# PIC32CX1012BZ24032 register map
Vendor: Microchip Technology; Series: BZ24; File version: 0
CPU: CM4 r0p1, little endian, MPU, FPU, 3 interrupt priority bits
Registers are 32-bit, read-write, reset 0x0 unless marked. A register's access mark holds for its fields unless they carry their own. Offsets are from the block's base; [hi:lo] are bit positions; {n}, {i} and the like mark numbered series; 'fields as' and 'values as' point back to an identical list.

## CFG
Base 0x44000000; register names take the prefix CFG_
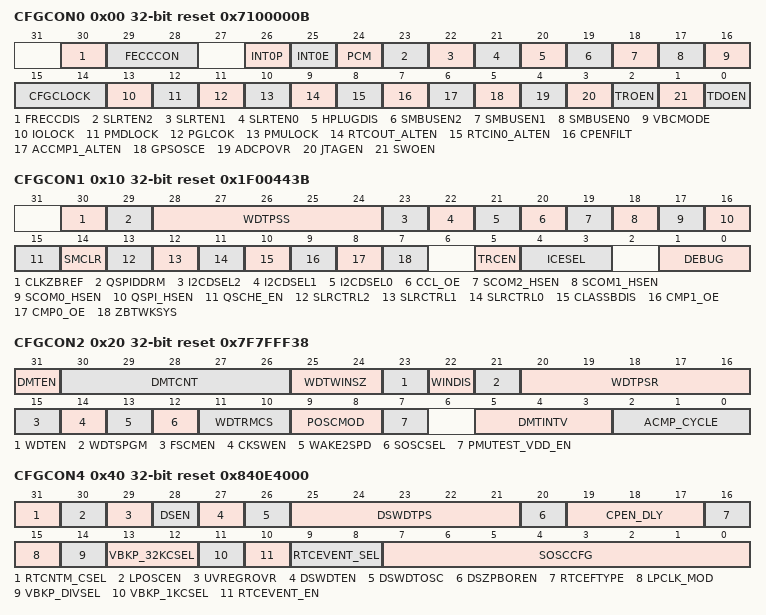
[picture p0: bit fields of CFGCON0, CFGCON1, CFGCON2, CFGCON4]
0x00 CFGCON0 reset 0x7100000B
  [30] FRECCDIS — Flex RAM ECC Control
  [29:28] FECCCON — Flash ECC Control
  [26] INT0P — INT0P Polarity
  [25] INT0E — INT0 Enable
  [24] PCM — PCHE I/D Cacheable Mode
  [23] SLRTEN2 — SLRT Enable for SERCOM2
  [22] SLRTEN1 — SLRT Enable for SERCOM1
  [21] SLRTEN0 — SLRT Enable for SERCOM0
  [20] HPLUGDIS — Hot Plugging Disable
  [19] SMBUSEN2 — SMBus Enable for SERCOM2
  [18] SMBUSEN1 — SMBus Enable for SERCOM1
  [17] SMBUSEN0 — SMBus Enable for SERCOM0
  [16] VBCMODE — VBC Operating Mode
  [15:14] CFGCLOCK — Configuration Register Lock
  [13] IOLOCK
  [12] PMDLOCK — Peripheral Module Disable (PMD) LOCK
  [11] PGLCOK — Permission Group LOCK
  [10] PMULOCK — PMU Controller Register LOCK
  [9] RTCOUT_ALTEN — RTCOUT Alternate Enable
  [8] RTCIN0_ALTEN — RTCIN0 Alternate Enable
  [7] CPENFILT — ADC CP Filter Enable
  [6] ACCMP1_ALTEN — AC CMP1 Alternate Enable
  [5] GPSOSCE — GPIO/SOSC Enable
  [4] ADCPOVR — ADC Charge Pump Override
  [3] JTAGEN — JTAG Enable
  [2] TROEN — Trace Output Enable
  [1] SWOEN — SWO enable on 2-wire debug interface
  [0] TDOEN — TDO enable for 2-wire JTAG
{0x4+0x10*i} CFGCON{i}CLR (i=0..2) — Bit clear register
{0x8+0x10*i} CFGCON{i}SET (i=0..2) — Bit set register
{0xC+0x10*i} CFGCON{i}INV (i=0..2) — Bit invert register
0x10 CFGCON1 reset 0x1F00443B
  [30] CLKZBREF — External Reference Clock ZB Enable
  [29] QSPIDDRM — QSPI DDR Mode Clock Enable
  [28:24] WDTPSS — Watchdog Timer Post-scale Select Sleep
  [23] I2CDSEL2 — I2C Delay Select for SERCOM2
  [22] I2CDSEL1 — I2C Delay Select for SERCOM1
  [21] I2CDSEL0 — I2C Delay Select for SERCOM0
  [20] CCL_OE — CCL Pads (via PPS) Output Enable
  [19] SCOM2_HSEN — SERCOM2 (Direct)High Speed Pin Enable
  [18] SCOM1_HSEN — SERCOM1 (Direct)High Speed Pin Enable
  [17] SCOM0_HSEN — SERCOM0 (Direct)High Speed Pin Enable
  [16] QSPI_HSEN — QSPI (Direct) Enable
  [15] QSCHE_EN — QSPI Address Space Cache Attribute
  [14] SMCLR — Selects CRU handling of MCLR Control
  [13] SLRCTRL2 — I2C Slew Rate Control for SERCOM2
  [12] SLRCTRL1 — I2C Slew Rate Control for SERCOM1
  [11] SLRCTRL0 — I2C Slew Rate Control for SERCOM0
  [10] CLASSBDIS — Disable CLASSB Device Functionality
  [9] CMP1_OE — Analog Comparator-1 Output Enable
  [8] CMP0_OE — Analog Comparator-0 Output Enable
  [7] ZBTWKSYS — ZBT Subsystem External Wake-up source
  [5] TRCEN — Trace Enable
  [4:3] ICESEL — EMUC/EMUD Communication Channel Select
  [1:0] DEBUG — Background Debugger Access Selection
0x20 CFGCON2 reset 0x7F7FFF38
  [31] DMTEN — Dead Man Timer Enable
  [30:26] DMTCNT — Dead Man Timer Count Select
  [25:24] WDTWINSZ — Watchdog Timer Window Size
  [23] WDTEN — Watchdog Timer Enable
  [22] WINDIS — Windowed Watchdog Timer Disable
  [21] WDTSPGM — Watchdog Timer Stop during Flash Programming
  [20:16] WDTPSR — Watchdog Timer Post-scale Select Run
  [15] FSCMEN — Fail-Safe Clock Monitor Enable
  [14] CKSWEN — Software Clock Switching Enable
  [13] WAKE2SPD — 2-Speed startup enabled in Sleep mode
  [12] SOSCSEL — SOSC Selection Configuration
  [11:10] WDTRMCS — WDT RUN Mode Clock Select
  [9:8] POSCMOD — Primary Oscillator Configuration
  [7] PMUTEST_VDD_EN — PMU Test Output or VDD/2 Enable via ADC IE12
  [5:3] DMTINTV — Dead Man Timer Count Window Interval
  [2:0] ACMP_CYCLE — AC SIB Comparator Result Wait Cycles
0x40 CFGCON4 reset 0x840E4000
  [31] RTCNTM_CSEL — RTC Counter Mode Clock Select
  [30] LPOSCEN — Low Power (Secondary) Oscillator Enable
  [29] UVREGROVR — ULPVREG Retention Mode Override
  [28] DSEN — Deep Sleep Bit Enable
  [27] DSWDTEN — Deep Sleep Watchdog Timer Enable
  [26] DSWDTOSC — Deep Sleep Watchdog Timer Reference Clock Select
  [25:21] DSWDTPS — Deep Sleep Watchdog Timer Postscale Select
  [20] DSZPBOREN — Deep Sleep Zero-Power BOR Enable
  [19:17] CPEN_DLY — Charge-pump ready digital delay
  [16] RTCEFTYPE — RTC Event Type
  [15] LPCLK_MOD — LPCLK modifier in counter/delay mode
  [14] VBKP_DIVSEL — VDDBUKPCORE LPCLK Clock Divider Selection
  [13:12] VBKP_32KCSEL — VDDBUKPCORE 32KHz clock source selection
  [11] VBKP_1KCSEL — VDDBUKPCORE LPCLK Clock Selection
  [10] RTCEVENT_EN — Pad Output Enable for MCHP legacy RTC event output
  [9:8] RTCEVENT_SEL — RTC Event Selection
  [7:0] SOSCCFG — SOSC Configuration
0x44 CFGCON4CLR — Bit clear register
0x48 CFGCON4SET — Bit set register
0x4C CFGCON4INV — Bit invert register
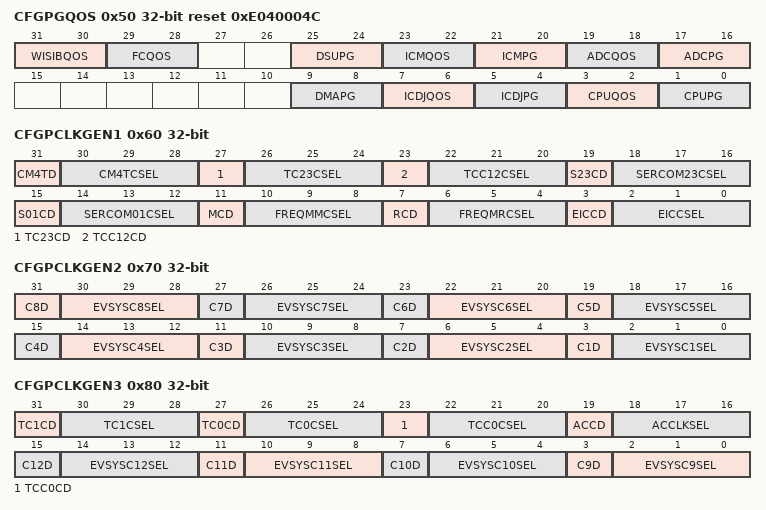
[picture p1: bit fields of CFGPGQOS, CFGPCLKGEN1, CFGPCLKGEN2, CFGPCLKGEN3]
0x50 CFGPGQOS reset 0xE040004C
  [31:30] WISIBQOS — Wireless SIB QOS Control
  [29:28] FCQOS — FC Controller QOS Control
  [25:24] DSUPG — DSU Permission Group
  [23:22] ICMQOS — ICM QOS Control
  [21:20] ICMPG — ICM Permission Group
  [19:18] ADCQOS — ADC Controller QOS Control
  [17:16] ADCPG — ADC Controller Permission Group
  [9:8] DMAPG — DMA (Rd/Wr) Permission Group
  [7:6] ICDJQOS — ICD-JTAG Bus QOS Control
  [5:4] ICDJPG — ICD-JTAG Permission Group
  [3:2] CPUQOS — CPU I/D and System Bus QOS Control
  [1:0] CPUPG — CPU (Code) Permission Group
0x54 CFGPGQOSCLR — Bit clear register
0x58 CFGPGQOSSET — Bit set register
0x5C CFGPGQOSINV — Bit invert register
0x60 CFGPCLKGEN1
  [31] CM4TD — CM4T Clock Disable
    1=ON (Enable PGCLK); 0=OFF (Disable PGCLK)
  [30:28] CM4TCSEL — CM4T Clock Selection
    0=NO_CLK (No Clock); {v}=REFO{v} (Reference Clock {v}) (v=1..6); 7=LPCLK (32 KHz Low Power Clock)
  [27] TC23CD — TC2/3 Clock Disable
    1=ON (Enable PGCLK); 0=OFF (Disable PGCLK)
  [26:24] TC23CSEL — TC2/3 Clock Selection
    values as CM4TCSEL
  [23] TCC12CD — TCC1/2 Clock Disable
    1=ON (Enable PGCLK); 0=OFF (Disable PGCLK)
  [22:20] TCC12CSEL — TCC1/2 Clock Selection
    values as CM4TCSEL
  [19] S23CD — SERCOM2/3 Clock Disable
    1=ON (Enable PGCLK); 0=OFF (Disable PGCLK)
  [18:16] SERCOM23CSEL — SERCOM2/3 Clock Selection
    values as CM4TCSEL
  [15] S01CD — SERCOM0/1 Clock Disable
    1=ON (Enable PGCLK); 0=OFF (Disable PGCLK)
  [14:12] SERCOM01CSEL — SERCOM0/1 Clock Selection
    values as CM4TCSEL
  [11] MCD — FREQMMC Clock Disable
    1=ON (Enable PGCLK); 0=OFF (Disable PGCLK)
  [10:8] FREQMMCSEL — FREQMMC Clock Selection
    values as CM4TCSEL
  [7] RCD — FREQMRC Clock Disable
    1=ON (Enable PGCLK); 0=OFF (Disable PGCLK)
  [6:4] FREQMRCSEL — FREQMRC Clock Selection
    values as CM4TCSEL
  [3] EICCD — EIC Clock Disable
    1=ON (Enable PGCLK); 0=OFF (Disable PGCLK)
  [2:0] EICCSEL — EIC Clock Selection
    values as CM4TCSEL
{0x54+0x10*i} CFGPCLKGEN{i}CLR (i=1..3) — Bit clear register
{0x58+0x10*i} CFGPCLKGEN{i}SET (i=1..3) — Bit set register
{0x5C+0x10*i} CFGPCLKGEN{i}INV (i=1..3) — Bit invert register
0x70 CFGPCLKGEN2
  [31] C8D — C8D Clock Disable
    1=ON (Enable PGCLK); 0=OFF (Disable PGCLK)
  [4n-2:4n-4] EVSYSC{n}SEL (n=1..8) — EVSYSC{n} Peripheral Clock Selection
    values as CFGPCLKGEN1.CM4TCSEL
  [27] C7D — C7D Clock Disable
    1=ON (Enable PGCLK); 0=OFF (Disable PGCLK)
  [4n-1] C{n}D (n=1..6) — EVSYSC{n} Clock Disable
    1=ON (Enable PGCLK); 0=OFF (Disable PGCLK)
0x80 CFGPCLKGEN3
  [31] TC1CD — TC1 Clock Disable
    1=ON (Enable PGCLK); 0=OFF (Disable PGCLK)
  [30:28] TC1CSEL — TC1 Peripheral Clock Selection
    values as CFGPCLKGEN1.CM4TCSEL
  [27] TC0CD — TC0 Clock Disable
    1=ON (Enable PGCLK); 0=OFF (Disable PGCLK)
  [26:24] TC0CSEL — TC0 Peripheral Clock Selection
    values as CFGPCLKGEN1.CM4TCSEL
  [23] TCC0CD — TCC0 Clock Disable
    1=ON (Enable PGCLK); 0=OFF (Disable PGCLK)
  [22:20] TCC0CSEL — TCC0 Peripheral Clock Selection
    values as CFGPCLKGEN1.CM4TCSEL
  [19] ACCD — AC Clock Disable
    1=ON (Enable PGCLK); 0=OFF (Disable PGCLK)
  [18:16] ACCLKSEL — AC Peripheral Clock Selection
    values as CFGPCLKGEN1.CM4TCSEL
  [4n-33] C{n}D (n=9..12) — C{n}D Clock Disable
    1=ON (Enable PGCLK); 0=OFF (Disable PGCLK)
  [4n-34:4n-36] EVSYSC{n}SEL (n=9..12) — EVSYSC{n} Peripheral Clock Selection
    values as CFGPCLKGEN1.CM4TCSEL
0x90 ID ro — Device ID
0xA0 USER_ID
  [15:0] USER_ID — User unique ID, readable using the JTAG USER_ID instruction
0xA4 USER_IDCLR — Bit clear register
0xA8 USER_IDSET — Bit set register
0xAC USER_IDINV — Bit invert register
0xB0 SYSKEY
  [31:0] SYSKEY — System Key
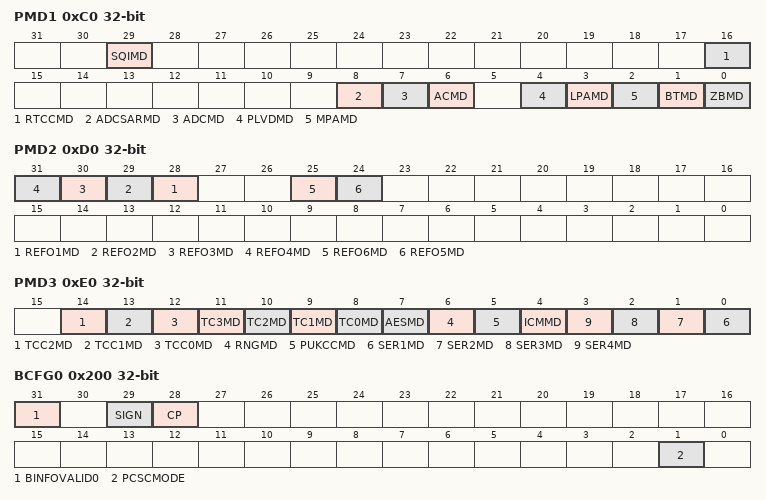
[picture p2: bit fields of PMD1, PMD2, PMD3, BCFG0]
0xC0 PMD1
  [29] SQIMD — SQI Module Disable
  [16] RTCCMD — RTCC Module Disable
  [8] ADCSARMD — Shared ADC SAR Core Module Disable
  [7] ADCMD — ADC Controller Module Disable
  [6] ACMD — AC Module Disable
  [4] PLVDMD — PLVD Module Disable
  [3] LPAMD — RF LPA Module Disable
  [2] MPAMD — RF MPA Module Disable
  [1] BTMD — Bluetooth Module Disable
  [0] ZBMD — ZigBee Module Disable
{0xB4+0x10*i} PMD{i}CLR (i=1..3) — Bit clear register
{0xB8+0x10*i} PMD{i}SET (i=1..3) — Bit set register
{0xBC+0x10*i} PMD{i}INV (i=1..3) — Bit invert register
0xD0 PMD2
  [n+27] REFO{n}MD (n=1..4) — Reference (Clock) Out {n} Module Disable
  [25] REFO6MD — Reference (Clock) Out 6 Module Disable
  [24] REFO5MD — Reference (Clock) Out 5 Module Disable
0xE0 PMD3
  [14] TCC2MD — TCC2 Module Disable
  [13] TCC1MD — TCC1 Module Disable
  [12] TCC0MD — TCC0 Module Disable
  [n+8] TC{n}MD (n=0..3) — TC{n} Module Disable
  [7] AESMD — AES Module Disable
  [6] RNGMD — TRNG Module Disable
  [5] PUKCCMD — PUKCC Module Disable
  [4] ICMMD — ICM Module Disable
  [n-1] SER{n}MD (n=1..4) — SERCOM{n} Module Disable
0x100 MISCSTAT reset 0x1000081
  [9] CLDORDY — CLDO Ready
0x200 BCFG0 ro
  [31] BINFOVALID0 — First 256-bit BCFG information Valid
  [29] SIGN — Flash SIGN
  [28] CP — Boot Code Protect
  [1] PCSCMODE — PCHE Single cache Mode

## Notices in the file
Copyright (c) 2017 Microchip Technology Inc.
SPDX-License-Identifier: Apache-2.0
Licensed under the Apache License, Version 2.0 (the "License");
you may not use this file except in compliance with the License.
You may obtain a copy of the License at
http://www.apache.org/licenses/LICENSE-2.0
Unless required by applicable law or agreed to in writing, software
distributed under the License is distributed on an "AS IS" BASIS,
WITHOUT WARRANTIES OR CONDITIONS OF ANY KIND, either express or implied.
See the License for the specific language governing permissions and
limitations under the License.
